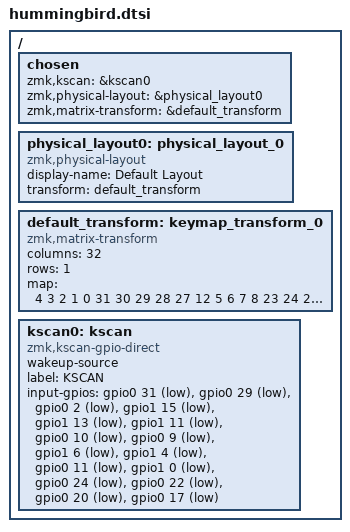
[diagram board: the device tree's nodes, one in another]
/ {
    chosen {
        zmk,kscan = &kscan0;
        zmk,physical-layout = &physical_layout0;
        zmk,matrix-transform = &default_transform;
    };

    physical_layout0: physical_layout_0 {
        compatible = "zmk,physical-layout";
        display-name = "Default Layout";
        transform = <&default_transform>;
    };

    default_transform: keymap_transform_0 {
        compatible = "zmk,matrix-transform";
        columns = <32>;
        rows = <1>;
        map = <
             4  3  2  1  0 /**/ 31 30 29 28 27
            12  5  6  7  8 /**/ 23 24 25 26 19
               11 10  9    /**/    22 21 20
                     13 14 /**/ 17 18
        >;
    };

    kscan0: kscan {
        compatible = "zmk,kscan-gpio-direct";
        wakeup-source;
        label = "KSCAN";
        input-gpios =
            <&gpio0 31 (GPIO_ACTIVE_LOW | GPIO_PULL_UP)>,
            <&gpio0 29 (GPIO_ACTIVE_LOW | GPIO_PULL_UP)>,
            <&gpio0  2 (GPIO_ACTIVE_LOW | GPIO_PULL_UP)>,
            <&gpio1 15 (GPIO_ACTIVE_LOW | GPIO_PULL_UP)>,
            <&gpio1 13 (GPIO_ACTIVE_LOW | GPIO_PULL_UP)>,
            <&gpio1 11 (GPIO_ACTIVE_LOW | GPIO_PULL_UP)>,
            <&gpio0 10 (GPIO_ACTIVE_LOW | GPIO_PULL_UP)>,
            <&gpio0  9 (GPIO_ACTIVE_LOW | GPIO_PULL_UP)>,

            <&gpio1  6 (GPIO_ACTIVE_LOW | GPIO_PULL_UP)>,
            <&gpio1  4 (GPIO_ACTIVE_LOW | GPIO_PULL_UP)>,
            <&gpio0 11 (GPIO_ACTIVE_LOW | GPIO_PULL_UP)>,
            <&gpio1  0 (GPIO_ACTIVE_LOW | GPIO_PULL_UP)>,
            <&gpio0 24 (GPIO_ACTIVE_LOW | GPIO_PULL_UP)>,
            <&gpio0 22 (GPIO_ACTIVE_LOW | GPIO_PULL_UP)>,
            <&gpio0 20 (GPIO_ACTIVE_LOW | GPIO_PULL_UP)>,
            <&gpio0 17 (GPIO_ACTIVE_LOW | GPIO_PULL_UP)>;
    };
};
